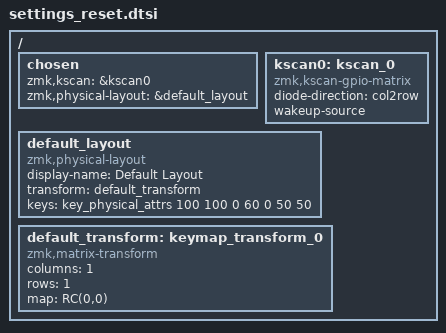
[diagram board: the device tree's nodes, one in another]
#include <dt-bindings/zmk/matrix_transform.h>
#include <physical_layouts.dtsi>

/ {
    chosen {
        zmk,kscan = &kscan0;
        zmk,physical-layout = &default_layout;
    };

    kscan0: kscan_0 {
        compatible = "zmk,kscan-gpio-matrix";
        diode-direction = "col2row";
        wakeup-source;
    };

    default_layout: default_layout {
        compatible = "zmk,physical-layout";
        display-name = "Default Layout";
        transform = <&default_transform>;

        keys  //                     w   h    x    y     rot    rx    ry
            = <&key_physical_attrs 100 100    0   60       0     50     50> // pinky bottom
            ;
    };

    default_transform: keymap_transform_0 {
        compatible = "zmk,matrix-transform";
        columns = <1>;
        rows = <1>;

        map = <
            RC(0,0)
        >;
    };
};

